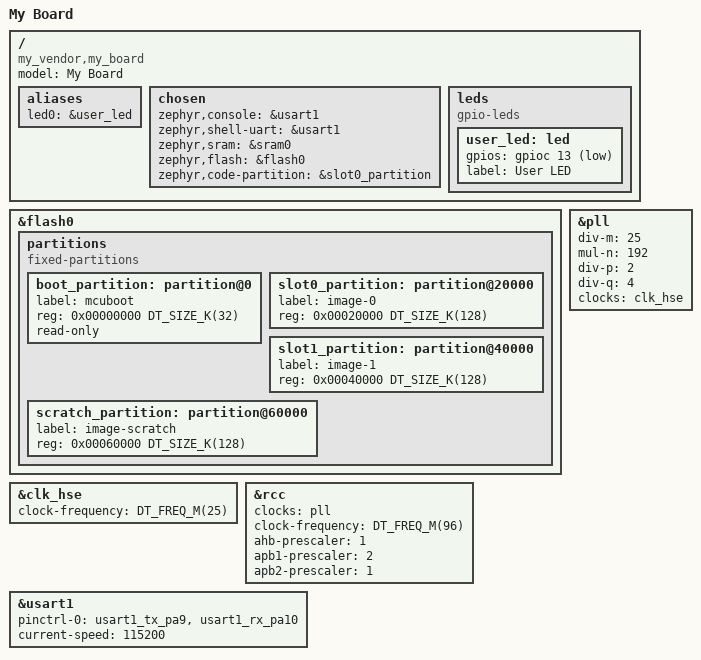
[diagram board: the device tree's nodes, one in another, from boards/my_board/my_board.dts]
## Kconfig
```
source "Kconfig.zephyr" # It includes all existing Kconfig files from Zephyr and its modules

menu "Application Configuration"
    
    # source "Kconfig.test"
    rsource "Kconfig.custom"    

    config APP_HEARTBEAT_PERIOD_MS
        int "Heartbeat period (100-2000ms)"
        range 100 2000
        default 500

endmenu

rsource "drivers/our_driver/Kconfig"
```

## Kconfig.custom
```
# menu "Application Configuration"

    # menu as config i.e. menu+checkbox with sub menu
    menuconfig LED_SUBSYSTEM
        bool "LED Subsystem"
        default y
    
        if LED_SUBSYSTEM
            choice
                prompt "LED blink sleep time"
                default BLINK_SLEEP_1000MS

                config BLINK_SLEEP_250MS
                    bool "250ms (very fast)"

                config BLINK_SLEEP_500MS
                    bool "500ms (fast)"

                config BLINK_SLEEP_1000MS
                    bool "1s (medium)"

                config BLINK_SLEEP_2000MS
                    bool "2s (slow)"
            endchoice

            config BLINK_SLEEP_TIME_MS # use this in code
                int # <-- No label / prompt = hidden
                default 250 if BLINK_SLEEP_250MS
                default 500 if BLINK_SLEEP_500MS
                default 1000 if BLINK_SLEEP_1000MS
                default 2000 if BLINK_SLEEP_2000MS
                default 0

            menuconfig LED_ADVANCED
                bool "Advanced LED settings"
                default y
            
                if LED_ADVANCED
                    # brightness
                    config LED_BRIGHTNESS
                        int "LED brightness (0-100)"
                        range 0 100
                        default 100

                    # fade duration
                    config LED_FADE_DURATION_MS
                        int "LED fade duration (ms)"
                        range 0 5000
                        default 500
                endif

                # menu: expert settings
                menu "Expert settings"
                    # visible if LED_ADVANCED # snake oil???
                    visible if LED_BRIGHTNESS != 0

                    config LED_DEBUG
                        bool "Enable LED debugging"

                    config LED_BLINK_PATTERN
                        bool "Custom blink pattern"
                        
                endmenu

        endif

# endmenu
```

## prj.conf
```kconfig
CONFIG_GPIO=y
CONFIG_LOG=y
CONFIG_SERIAL=y
CONFIG_CONSOLE=y
CONFIG_UART_CONSOLE=y
# CONFIG_BLINK_SLEEP_TIME_MS=250
CONFIG_OUR_DRIVER=y

CONFIG_SHELL=y
CONFIG_SHELL_BACKEND_SERIAL=y
# CONFIG_SHELL_MINIMAL=Y 

CONFIG_SHELL_CMDS=y
CONFIG_SHELL_TAB=y
CONFIG_SHELL_TAB_AUTOCOMPLETION=y
CONFIG_SHELL_HISTORY=y
CONFIG_SHELL_LOG_BACKEND=y
```

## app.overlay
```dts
/ {
    aliases {
        app-led = &user_led;
    };

    our_driver0: our_driver {
        compatible = "our,driver";
        status = "okay";
    };
    our_driver1: our_driver1 {
        compatible = "our,driver";
        status = "okay";
    };
};
```

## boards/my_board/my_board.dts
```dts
/dts-v1/;
#include <st/f4/stm32f411Xe.dtsi>
#include <st/f4/stm32f411c(c-e)ux-pinctrl.dtsi>
#include <zephyr/dt-bindings/input/input-event-codes.h>

/ {
	model = "My Board";
	compatible = "my_vendor,my_board";

	aliases {
		led0 = &user_led;
	};

	chosen {
		zephyr,console = &usart1;
		zephyr,shell-uart = &usart1;
		zephyr,sram = &sram0;
		zephyr,flash = &flash0;
	};

	chosen {
		zephyr,flash = &flash0;
		zephyr,sram = &sram0; /* Point to regular RAM */
		zephyr,code-partition = &slot0_partition; /* Regular application slot */
	};

	leds {
		compatible = "gpio-leds";

		user_led: led {
			gpios = <&gpioc 13 GPIO_ACTIVE_LOW>;
			label = "User LED";
		};
	};

};

&flash0 {
	partitions {
		compatible = "fixed-partitions";
		#address-cells = <1>;
		#size-cells = <1>;

		boot_partition: partition@0 {
			label = "mcuboot";
			reg = <0x00000000 DT_SIZE_K(32)>;
			read-only;
		};

		/*
		 * The flash starting at offset 0x00008000 and ending at
		 * offset 0x0001ffff (sectors 2 through 4) is reserved for
		 * use by the application.
		 */

		slot0_partition: partition@20000 {
			label = "image-0";
			reg = <0x00020000 DT_SIZE_K(128)>;
		};

		slot1_partition: partition@40000 {
			label = "image-1";
			reg = <0x00040000 DT_SIZE_K(128)>;
		};

		scratch_partition: partition@60000 {
			label = "image-scratch";
			reg = <0x00060000 DT_SIZE_K(128)>;
		};
	};
};

&clk_hse {
	clock-frequency = <DT_FREQ_M(25)>;
	status = "okay";
};

&pll {
	div-m = <25>;
	mul-n = <192>;
	div-p = <2>;
	div-q = <4>;
	clocks = <&clk_hse>;
	status = "okay";
};

&rcc {
	clocks = <&pll>;
	clock-frequency = <DT_FREQ_M(96)>;
	ahb-prescaler = <1>;
	apb1-prescaler = <2>;
	apb2-prescaler = <1>;
};

&usart1 {
	pinctrl-0 = <&usart1_tx_pa9 &usart1_rx_pa10>;
	pinctrl-names = "default";
	status = "okay";
	current-speed = <115200>;
};
```

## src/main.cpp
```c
// #include <zephyr/drivers/gpio.h>
#include <zephyr/kernel.h>
#include <zephyr/logging/log.h>
#include <zephyr/drivers/sensor.h>
#include <zephyr/shell/shell.h>
#include "../drivers/our_driver/our_driver_task2.h"

// #define SLEEP_TIME_MS 500

LOG_MODULE_REGISTER(main, LOG_LEVEL_INF);

namespace {
    void turn_on_led() {
        const struct device *driver = DEVICE_DT_GET(DT_NODELABEL(our_driver0));
        struct sensor_value val;
        auto ret = sensor_sample_fetch(driver);
        LOG_INF("Channel ret: %d\n", ret);
    }

    void turn_off_led() {
        const struct device *driver = DEVICE_DT_GET(DT_NODELABEL(our_driver0));
        struct sensor_value val;
        auto ret = sensor_channel_get(driver, SENSOR_CHAN_AMBIENT_TEMP, &val);
        LOG_INF("Channel ret: %d\n", ret);
    }
}

/* ############################## SHELL BEGIN ############################## */
static int cmd_version(const struct shell *sh, size_t argc, char **argv) {
    shell_print(sh, "App version: v1.0.0");
    return 0;
}
SHELL_CMD_REGISTER(version, NULL, "Show app version", cmd_version);

static int cmd_handler(const struct shell *sh, size_t argc, char **argv) {
    ARG_UNUSED(argc);
    ARG_UNUSED(argv);

    // Simple text output
    shell_print(sh, "Hello from the shell!!");

    // Colored/categorized text output
    shell_info(sh, "Information message!");
    shell_warn(sh, "Warning message!");
    shell_error(sh, "Error message!");

    // Formatted output
    shell_fprintf(sh, SHELL_INFO, "Value: %d\n ", 123);

    return 0;
}
SHELL_CMD_REGISTER(test, NULL, "Test command", cmd_handler);

/* salue sub command action */
static int cmd_demo_salute(const struct shell *sh, size_t argc, char **argv) {
    shell_print(sh, "Good Afternoon!");
    return 0;
}

/* parse sub command action */
static int cmd_demo_parse(const struct shell *sh, size_t argc, char **argv) {
    shell_print(sh, "argc: %d", argc);

    for (size_t i = 0; i < argc; i++) {
        shell_print(sh, "\t argv[%d] = %s", i, argv[i]);
    }

    return 0;
}

/* Create subcommand array for demo command */
SHELL_STATIC_SUBCMD_SET_CREATE(sub_demo,
    SHELL_CMD(salute, NULL, "Print salute message.", cmd_demo_salute),
    SHELL_CMD(parse, NULL, "Print all arguments.", cmd_demo_parse),
    SHELL_SUBCMD_SET_END
);

/* Register root command demo with sub commands */
SHELL_CMD_REGISTER(demo, &sub_demo, "Demo commands", NULL);
/* ############################## SHELL END ############################## */

int main(void) {
    uint32_t counter = 0;

    while (1) {
        // turn_on_led();
        // k_msleep(CONFIG_APP_HEARTBEAT_PERIOD_MS);

        // turn_off_led();
        // k_msleep(CONFIG_APP_HEARTBEAT_PERIOD_MS);

        // toggle_led(&counter); // calling from our_driver_task2.h interface, implemented in our_driver.c
        
        LOG_INF("counter: %d\n", counter);
        k_msleep(CONFIG_APP_HEARTBEAT_PERIOD_MS);
    }

    return 0;
}
```
